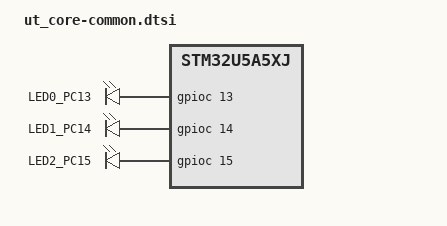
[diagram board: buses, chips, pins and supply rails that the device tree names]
/* UT-CORE (STM32U5A5xx) Common Configuration
 * Shared hardware definitions: Clocks, LEDs, and GPIOs.
 */

/dts-v1/;

#include <st/u5/stm32u5a5Xj.dtsi>
#include <zephyr/dt-bindings/gpio/gpio.h>
#include <zephyr/dt-bindings/pinctrl/stm32-pinctrl.h>

/ {
	/* Map logical LED names to physical GPIO pins. */
	leds {
		compatible = "gpio-leds";

		led0: led_0 {
			gpios = <&gpioc 13 GPIO_ACTIVE_HIGH>;
			label = "LED0_PC13";
		};

		led1: led_1 {
			gpios = <&gpioc 14 GPIO_ACTIVE_HIGH>;
			label = "LED1_PC14";
		};

		led2: led_2 {
			gpios = <&gpioc 15 GPIO_ACTIVE_HIGH>;
			label = "LED2_PC15";
		};
	};
};

/* Oscillators: Disable unused crystals/clocks to prevent startup hangs. */
&clk_hsi48 { status = "disabled"; }; /* Internal 48MHz (USB) */
&clk_hse { status = "disabled"; };   /* External High Speed Crystal */
&clk_lse { status = "disabled"; };   /* External Low Speed Crystal */

/* Enable the Multi-Speed Internal (MSI) oscillator as the system source. */
&clk_msis {
  status = "okay";
};

/* System Clock (RCC) Configuration
 * Run at a conservative 4MHz off the MSI to ensure stable boot. */
&rcc {
  clocks = <&clk_msis>;
  clock-frequency = <DT_FREQ_M(4)>;
  ahb-prescaler = <1>;
  apb1-prescaler = <1>;
  apb2-prescaler = <1>;
  apb3-prescaler = <1>;
};

/* Enable GPIOC peripheral clock so the LEDs can toggle. */
&gpioc {
    status = "okay";
};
